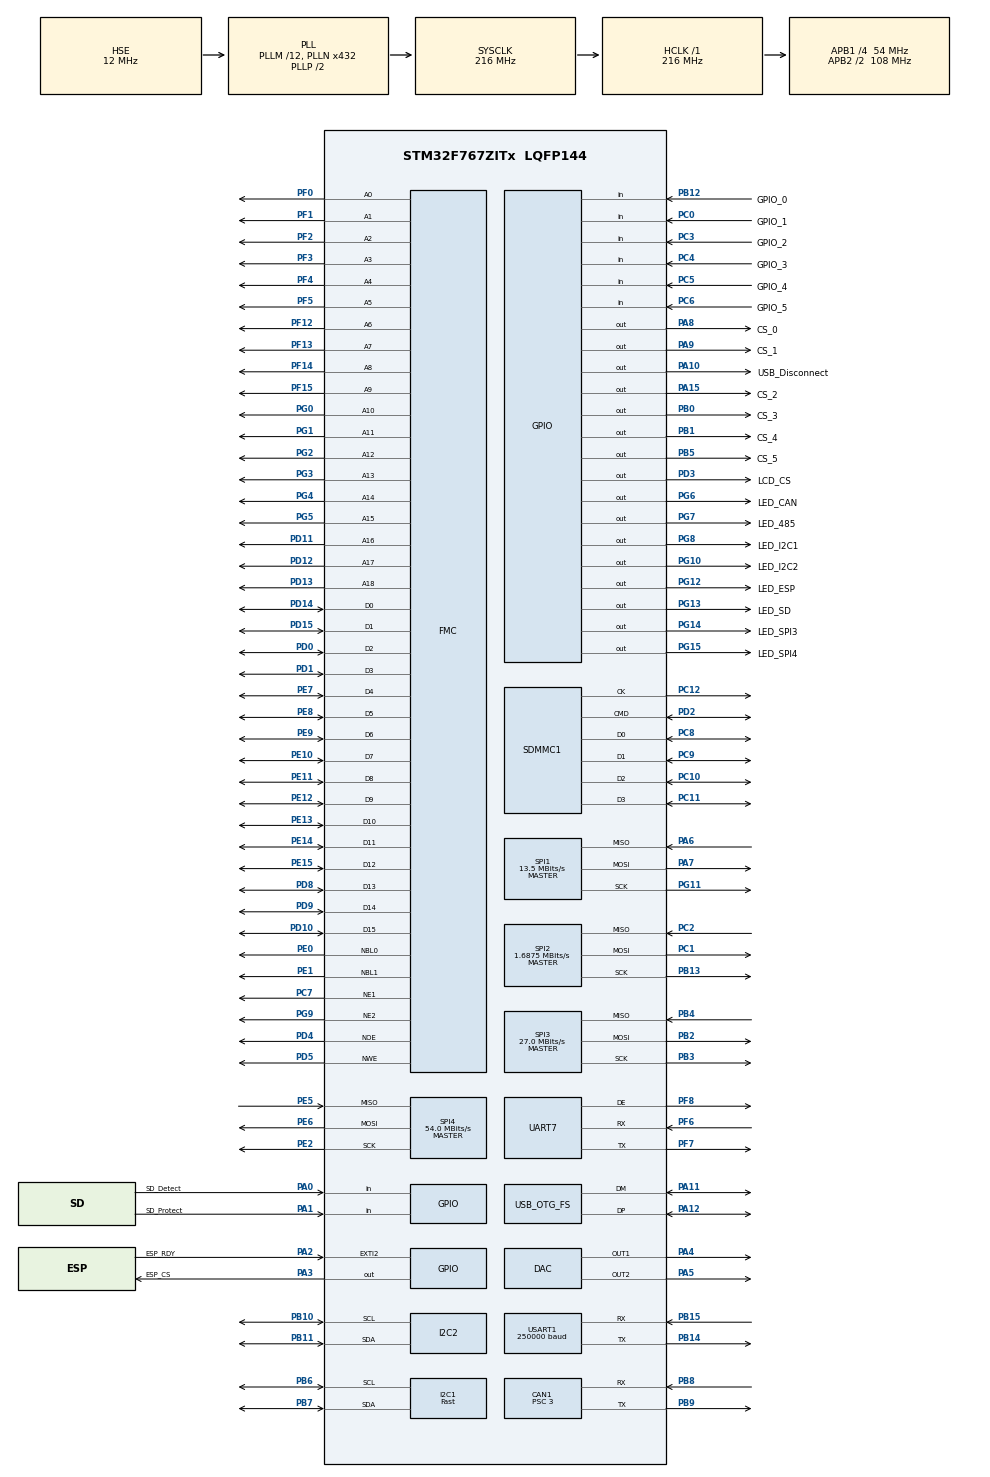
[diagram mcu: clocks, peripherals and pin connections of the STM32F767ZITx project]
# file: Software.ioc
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CAN1.BS1=CAN_BS1_15TQ
CAN1.BS2=CAN_BS2_2TQ
CAN1.CalculateBaudRate=1000000
CAN1.CalculateTimeBit=1000
CAN1.CalculateTimeQuantum=55.55555555555556
CAN1.NART=DISABLE
CAN1.Prescaler=3
Dma.Request0=USART1_TX
Dma.USART1_TX.0.Direction=DMA_MEMORY_TO_PERIPH
Dma.USART1_TX.0.FIFOMode=DMA_FIFOMODE_DISABLE
Dma.USART1_TX.0.Instance=DMA2_Stream7
Dma.USART1_TX.0.MemDataAlignment=DMA_MDATAALIGN_BYTE
Dma.USART1_TX.0.MemInc=DMA_MINC_ENABLE
Dma.USART1_TX.0.Mode=DMA_NORMAL
Dma.USART1_TX.0.PeriphDataAlignment=DMA_PDATAALIGN_BYTE
Dma.USART1_TX.0.PeriphInc=DMA_PINC_DISABLE
Dma.USART1_TX.0.Priority=DMA_PRIORITY_MEDIUM
FMC.ExtendedMode1=FMC_EXTENDED_MODE_DISABLE
I2C1.I2C_Speed_Mode=I2C_Fast
I2C1.Timing=0x6000030D
I2C2.Timing=0x20404768
Mcu.Family=STM32F7
Mcu.Name=STM32F767ZITx
Mcu.Package=LQFP144
NVIC.CAN1_RX0_IRQn=true\:0\:0\:false\:false\:true\:true\:true\:true
NVIC.DMA2_Stream7_IRQn=true\:0\:0\:false\:false\:true\:false\:true\:true
NVIC.OTG_FS_IRQn=true\:0\:0\:false\:false\:true\:true\:true\:true
NVIC.PriorityGroup=NVIC_PRIORITYGROUP_4
NVIC.USART1_IRQn=true\:0\:0\:false\:false\:true\:true\:true\:true
PA0/WKUP.GPIO_Label=SD_Detect
PA0/WKUP.Signal=GPIO_Input
PA1.GPIO_Label=SD_Protect
PA1.Signal=GPIO_Input
PA10.GPIO_Label=USB_Disconnect
PA10.Signal=GPIO_Output
PA11.Mode=Device_Only
PA11.Signal=USB_OTG_FS_DM
PA12.Mode=Device_Only
PA12.Signal=USB_OTG_FS_DP
PA13.Mode=Serial_Wire
PA13.Signal=SYS_JTMS-SWDIO
PA14.Mode=Serial_Wire
PA14.Signal=SYS_JTCK-SWCLK
PA15.GPIO_Label=CS_2
PA15.Signal=GPIO_Output
PA2.GPIO_Label=ESP_RDY
PA2.Signal=GPXTI2
PA3.GPIO_Label=ESP_CS
PA3.Signal=GPIO_Output
PA4.Signal=COMP_DAC1_group
PA5.Signal=COMP_DAC2_group
PA6.Mode=Full_Duplex_Master
PA6.Signal=SPI1_MISO
PA7.Mode=Full_Duplex_Master
PA7.Signal=SPI1_MOSI
PA8.GPIO_Label=CS_0
PA8.Signal=GPIO_Output
PA9.GPIO_Label=CS_1
PA9.Signal=GPIO_Output
PB0.GPIO_Label=CS_3
PB0.Signal=GPIO_Output
PB1.GPIO_Label=CS_4
PB1.Signal=GPIO_Output
PB10.Mode=I2C
PB10.Signal=I2C2_SCL
PB11.Mode=I2C
PB11.Signal=I2C2_SDA
PB12.GPIO_Label=GPIO_0
PB12.Signal=GPIO_Input
PB13.Mode=Full_Duplex_Master
PB13.Signal=SPI2_SCK
PB14.Mode=Asynchronous
PB14.Signal=USART1_TX
PB15.Mode=Asynchronous
PB15.Signal=USART1_RX
PB2.Mode=Full_Duplex_Master
PB2.Signal=SPI3_MOSI
PB3.Mode=Full_Duplex_Master
PB3.Signal=SPI3_SCK
PB4.Mode=Full_Duplex_Master
PB4.Signal=SPI3_MISO
PB5.GPIO_Label=CS_5
PB5.Signal=GPIO_Output
PB6.Mode=I2C
PB6.Signal=I2C1_SCL
PB7.Mode=I2C
PB7.Signal=I2C1_SDA
PB8.Mode=CAN_Activate
PB8.Signal=CAN1_RX
PB9.Mode=CAN_Activate
PB9.Signal=CAN1_TX
PC0.GPIO_Label=GPIO_1
PC0.Signal=GPIO_Input
PC1.Mode=Full_Duplex_Master
PC1.Signal=SPI2_MOSI
PC10.Mode=SD_4_bits_Wide_bus
PC10.Signal=SDMMC1_D2
PC11.Mode=SD_4_bits_Wide_bus
PC11.Signal=SDMMC1_D3
PC12.Mode=SD_4_bits_Wide_bus
PC12.Signal=SDMMC1_CK
PC2.Mode=Full_Duplex_Master
PC2.Signal=SPI2_MISO
PC3.GPIO_Label=GPIO_2
PC3.Signal=GPIO_Input
PC4.GPIO_Label=GPIO_3
PC4.Signal=GPIO_Input
PC5.GPIO_Label=GPIO_4
PC5.Signal=GPIO_Input
PC6.GPIO_Label=GPIO_5
PC6.Signal=GPIO_Input
PC7.Mode=NorPsramChipSelect1_1
PC7.Signal=FMC_NE1
PC8.Mode=SD_4_bits_Wide_bus
PC8.Signal=SDMMC1_D0
PC9.Mode=SD_4_bits_Wide_bus
PC9.Signal=SDMMC1_D1
PD0.Signal=FMC_D2_DA2
PD1.Signal=FMC_D3_DA3
PD10.Signal=FMC_D15_DA15
PD11.Signal=FMC_A16_CLE
PD12.Signal=FMC_A17_ALE
PD13.Signal=FMC_A18
PD14.Signal=FMC_D0_DA0
PD15.Signal=FMC_D1_DA1
PD2.Mode=SD_4_bits_Wide_bus
PD2.Signal=SDMMC1_CMD
PD3.GPIO_Label=LCD_CS
PD3.PinState=GPIO_PIN_SET
PD3.Signal=GPIO_Output
PD4.Signal=FMC_NOE
PD5.Signal=FMC_NWE
PD8.Signal=FMC_D13_DA13
PD9.Signal=FMC_D14_DA14
PE0.Signal=FMC_NBL0
PE1.Signal=FMC_NBL1
PE10.Signal=FMC_D7_DA7
PE11.Signal=FMC_D8_DA8
PE12.Signal=FMC_D9_DA9
PE13.Signal=FMC_D10_DA10
PE14.Signal=FMC_D11_DA11
PE15.Signal=FMC_D12_DA12
PE2.Mode=Full_Duplex_Master
PE2.Signal=SPI4_SCK
PE5.Mode=Full_Duplex_Master
PE5.Signal=SPI4_MISO
PE6.Mode=Full_Duplex_Master
PE6.Signal=SPI4_MOSI
PE7.Signal=FMC_D4_DA4
PE8.Signal=FMC_D5_DA5
PE9.Signal=FMC_D6_DA6
PF0.Signal=FMC_A0
PF1.Signal=FMC_A1
PF12.Signal=FMC_A6
PF13.Signal=FMC_A7
PF14.Signal=FMC_A8
PF15.Signal=FMC_A9
PF2.Signal=FMC_A2
PF3.Signal=FMC_A3
PF4.Signal=FMC_A4
PF5.Signal=FMC_A5
PF6.Mode=Asynchronous
PF6.Signal=UART7_RX
PF7.Mode=Asynchronous
PF7.Signal=UART7_TX
PF8.Mode=Hardware Flow Control (RS485)
PF8.Signal=UART7_DE
PG0.Signal=FMC_A10
PG1.Signal=FMC_A11
PG10.GPIO_Label=LED_I2C2
PG10.Signal=GPIO_Output
PG11.Mode=Full_Duplex_Master
PG11.Signal=SPI1_SCK
PG12.GPIO_Label=LED_ESP
PG12.Signal=GPIO_Output
PG13.GPIO_Label=LED_SD
PG13.Signal=GPIO_Output
PG14.GPIO_Label=LED_SPI3
PG14.Signal=GPIO_Output
PG15.GPIO_Label=LED_SPI4
PG15.Signal=GPIO_Output
PG2.Signal=FMC_A12
PG3.Signal=FMC_A13
PG4.Signal=FMC_A14_BA0
PG5.Signal=FMC_A15_BA1
PG6.GPIO_Label=LED_CAN
PG6.Signal=GPIO_Output
PG7.GPIO_Label=LED_485
PG7.Signal=GPIO_Output
PG8.GPIO_Label=LED_I2C1
PG8.Signal=GPIO_Output
PG9.Mode=NorPsramChipSelect2_2
PG9.Signal=FMC_NE2
PH0/OSC_IN.Mode=HSE-External-Oscillator
PH0/OSC_IN.Signal=RCC_OSC_IN
PH1/OSC_OUT.Mode=HSE-External-Oscillator
PH1/OSC_OUT.Signal=RCC_OSC_OUT
ProjectManager.HeapSize=0x200
ProjectManager.StackSize=0x400
ProjectManager.TargetToolchain=Other Toolchains (GPDSC)
RCC.AHBFreq_Value=216000000
RCC.APB1CLKDivider=RCC_HCLK_DIV4
RCC.APB1Freq_Value=54000000
RCC.APB1TimFreq_Value=108000000
RCC.APB2CLKDivider=RCC_HCLK_DIV2
RCC.APB2Freq_Value=108000000
RCC.APB2TimFreq_Value=216000000
RCC.CortexFreq_Value=216000000
RCC.HCLKFreq_Value=216000000
RCC.HSE_VALUE=12000000
RCC.HSI_VALUE=16000000
RCC.LSE_VALUE=32768
RCC.PLLM=12
RCC.PLLN=432
RCC.PLLQ=9
RCC.PLLSAIN=96
RCC.RCC_RTC_Clock_Source_FROM_HSE=RCC_RTCCLKSOURCE_HSE_DIV30
RCC.SDMMCClockSelection=RCC_SDMMC1CLKSOURCE_CLK48
RCC.SYSCLKFreq_VALUE=216000000
RCC.SYSCLKSource=RCC_SYSCLKSOURCE_PLLCLK
RCC.USBFreq_Value=48000000
RCC.VCOOutputFreq_Value=432000000
RTC.SynchPrediv=0xff
SH.COMP_DAC1_group.0=DAC_OUT1,DAC_OUT1
SH.COMP_DAC2_group.0=DAC_OUT2,DAC_OUT2
SH.FMC_A0.0=FMC_A0,19b-a2
SH.FMC_A0.1=FMC_A0,A0_1
SH.FMC_A1.0=FMC_A1,19b-a2
SH.FMC_A10.0=FMC_A10,19b-a2
SH.FMC_A11.0=FMC_A11,19b-a2
SH.FMC_A12.0=FMC_A12,19b-a2
SH.FMC_A13.0=FMC_A13,19b-a2
SH.FMC_A14_BA0.0=FMC_A14,19b-a2
SH.FMC_A15_BA1.0=FMC_A15,19b-a2
SH.FMC_A16_CLE.0=FMC_A16,19b-a2
SH.FMC_A17_ALE.0=FMC_A17,19b-a2
SH.FMC_A18.0=FMC_A18,19b-a2
SH.FMC_A2.0=FMC_A2,19b-a2
SH.FMC_A3.0=FMC_A3,19b-a2
SH.FMC_A4.0=FMC_A4,19b-a2
SH.FMC_A5.0=FMC_A5,19b-a2
SH.FMC_A6.0=FMC_A6,19b-a2
SH.FMC_A7.0=FMC_A7,19b-a2
SH.FMC_A8.0=FMC_A8,19b-a2
SH.FMC_A9.0=FMC_A9,19b-a2
SH.FMC_D0_DA0.0=FMC_D0,16b-d1
SH.FMC_D0_DA0.1=FMC_D0,16b-d2
SH.FMC_D10_DA10.0=FMC_D10,16b-d1
SH.FMC_D10_DA10.1=FMC_D10,16b-d2
SH.FMC_D11_DA11.0=FMC_D11,16b-d1
SH.FMC_D11_DA11.1=FMC_D11,16b-d2
SH.FMC_D12_DA12.0=FMC_D12,16b-d1
SH.FMC_D12_DA12.1=FMC_D12,16b-d2
SH.FMC_D13_DA13.0=FMC_D13,16b-d1
SH.FMC_D13_DA13.1=FMC_D13,16b-d2
SH.FMC_D14_DA14.0=FMC_D14,16b-d1
SH.FMC_D14_DA14.1=FMC_D14,16b-d2
SH.FMC_D15_DA15.0=FMC_D15,16b-d1
SH.FMC_D15_DA15.1=FMC_D15,16b-d2
SH.FMC_D1_DA1.0=FMC_D1,16b-d1
SH.FMC_D1_DA1.1=FMC_D1,16b-d2
SH.FMC_D2_DA2.0=FMC_D2,16b-d1
SH.FMC_D2_DA2.1=FMC_D2,16b-d2
SH.FMC_D3_DA3.0=FMC_D3,16b-d1
SH.FMC_D3_DA3.1=FMC_D3,16b-d2
SH.FMC_D4_DA4.0=FMC_D4,16b-d1
SH.FMC_D4_DA4.1=FMC_D4,16b-d2
SH.FMC_D5_DA5.0=FMC_D5,16b-d1
SH.FMC_D5_DA5.1=FMC_D5,16b-d2
SH.FMC_D6_DA6.0=FMC_D6,16b-d1
SH.FMC_D6_DA6.1=FMC_D6,16b-d2
SH.FMC_D7_DA7.0=FMC_D7,16b-d1
SH.FMC_D7_DA7.1=FMC_D7,16b-d2
SH.FMC_D8_DA8.0=FMC_D8,16b-d1
SH.FMC_D8_DA8.1=FMC_D8,16b-d2
SH.FMC_D9_DA9.0=FMC_D9,16b-d1
SH.FMC_D9_DA9.1=FMC_D9,16b-d2
SH.FMC_NBL0.0=FMC_NBL0,2ByteEnable2
SH.FMC_NBL1.0=FMC_NBL1,2ByteEnable2
SH.FMC_NOE.0=FMC_NOE,Lcd1
SH.FMC_NOE.1=FMC_NOE,Sram2
SH.FMC_NWE.0=FMC_NWE,Lcd1
SH.FMC_NWE.1=FMC_NWE,Sram2
SPI1.BaudRatePrescaler=SPI_BAUDRATEPRESCALER_8
SPI1.CalculateBaudRate=13.5 MBits/s
SPI1.DataSize=SPI_DATASIZE_8BIT
SPI1.Direction=SPI_DIRECTION_2LINES
SPI1.Mode=SPI_MODE_MASTER
SPI1.VirtualType=VM_MASTER
SPI2.BaudRatePrescaler=SPI_BAUDRATEPRESCALER_32
SPI2.CalculateBaudRate=1.6875 MBits/s
SPI2.Direction=SPI_DIRECTION_2LINES
SPI2.Mode=SPI_MODE_MASTER
SPI2.VirtualType=VM_MASTER
SPI3.BaudRatePrescaler=SPI_BAUDRATEPRESCALER_2
SPI3.CalculateBaudRate=27.0 MBits/s
SPI3.Direction=SPI_DIRECTION_2LINES
SPI3.Mode=SPI_MODE_MASTER
SPI3.VirtualType=VM_MASTER
SPI4.BaudRatePrescaler=SPI_BAUDRATEPRESCALER_2
SPI4.CalculateBaudRate=54.0 MBits/s
SPI4.Direction=SPI_DIRECTION_2LINES
SPI4.Mode=SPI_MODE_MASTER
SPI4.VirtualType=VM_MASTER
TIM1.Prescaler=216
USART1.BaudRate=250000
USART1.VirtualMode-Asynchronous=VM_ASYNC
USB_DEVICE.CLASS_NAME_FS=CDC
USB_DEVICE.VirtualMode-CDC_FS=Cdc
USB_DEVICE.VirtualModeFS=Cdc_FS
USB_OTG_FS.VirtualMode=Device_Only
VP_FATFS_VS_SDIO.Mode=SDIO
VP_RTC_VS_RTC_Activate.Mode=RTC_Enabled
VP_RTC_VS_RTC_Calendar.Mode=RTC_Calendar
VP_TIM1_VS_ClockSourceINT.Mode=Internal
VP_USB_DEVICE_VS_USB_DEVICE_CDC_FS.Mode=CDC_FS
board=custom

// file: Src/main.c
/* USER CODE BEGIN Header */
/**
  ******************************************************************************
  * @file           : main.c
  * @brief          : Main program body
  ******************************************************************************
  * @attention
  *
  * <h2><center>&copy; Copyright (c) 2022 STMicroelectronics.
  * All rights reserved.</center></h2>
  *
  * This software component is licensed by ST under Ultimate Liberty license
  * SLA0044, the "License"; You may not use this file except in compliance with
  * the License. You may obtain a copy of the License at:
  *                             www.st.com/SLA0044
  *
  ******************************************************************************
  */
/* USER CODE END Header */
#include "main.h"
#include "can.h"
#include "dac.h"
#include "dma.h"
#include "fatfs.h"
#include "i2c.h"
#include "rtc.h"
#include "sdmmc.h"
#include "spi.h"
#include "tim.h"
#include "usart.h"
#include "usb_device.h"
#include "gpio.h"
#include "fmc.h"

/* USER CODE BEGIN Includes */
#include "usbd_cdc_if.h"
#include "tft.h"
#include "modlab.h"
#include <stdio.h>
#include "usb_mon.h"

/* USER CODE END Includes */

/* USER CODE BEGIN PV */

uint16_t counter;
uint32_t tick_loop;
uint32_t tick_loop_old;

uint8_t address = 0;

/* USER CODE END PV */

void SystemClock_Config(void);

int main(void)
{

  /* MCU Configuration--------------------------------------------------------*/

  /* Reset of all peripherals, Initializes the Flash interface and the Systick. */
  HAL_Init();

  /* Configure the system clock */
  SystemClock_Config();

  /* Initialize all configured peripherals */
  MX_GPIO_Init();
  MX_SDMMC1_SD_Init();
  MX_FATFS_Init();
  MX_CAN1_Init();
  MX_I2C1_Init();
  MX_I2C2_Init();
  MX_RTC_Init();
  MX_SPI1_Init();
  MX_SPI2_Init();
  MX_UART7_Init();
  MX_DAC_Init();
  MX_FMC_Init();
  MX_SPI3_Init();
  MX_SPI4_Init();
  MX_TIM1_Init();
  MX_USB_DEVICE_Init();
  MX_DMA_Init();
  MX_USART1_UART_Init();
  /* USER CODE BEGIN 2 */

  timer_init();

  LEDs_Off();
  HAL_GPIO_WritePin(USB_Disconnect_GPIO_Port, USB_Disconnect_Pin, 1);
  HAL_Delay(200);
  //HAL_GPIO_WritePin(USB_Disconnect_GPIO_Port, USB_Disconnect_Pin, 0);

  CAN_Filter();
  HAL_CAN_Start(&hcan1);
  HAL_CAN_ActivateNotification(&hcan1, CAN_IT_RX_FIFO0_MSG_PENDING);

  tft_init();
  HAL_UART_Receive_IT(&huart1, RxBuffer, 1); // Get TFT Command
  __enable_irq();

  HAL_Delay(500);
	scan_dev();

//https://controllerstech.com/can-protocol-in-stm32/

  HAL_Delay(500);
  tft_reset();

  tick_loop = HAL_GetTick() + 1000;
  /* USER CODE END 2 */

  /* Infinite loop */
  /* USER CODE BEGIN WHILE */
  while (1)
  {
    if((tft_cmd == CMD_PAGESET) && (setdata == 1))
    {
      HAL_Delay(10);
      enableblock = 1;
      setdata = 0;
    }

    switch (tft_page)
    {
      case PAGE_MAIN:
        main_page_loop();
        break;
      case PAGE_DTEST:
        diode_page_loop();
        break;
      case PAGE_FGEN:
        fgen_page_loop();
        break;
      case PAGE_SYMPSU:
        sympsu_page_loop();
        break;
      case PAGE_SMPS:
        smps_page_loop();
        break;
      case PAGE_LOAD:
        load_page_loop();
        break;
    }

    if(tick_loop < (HAL_GetTick() - 1000))
    {
      tick_loop = HAL_GetTick();
      sprintf(out_buf, "USB Test Zyklus, Tick-Time = %d\n", HAL_GetTick());
      CDC_Transmit_FS((uint8_t *)out_buf, strlen(out_buf));
    }

  }
  /* USER CODE END 3 */
}

void SystemClock_Config(void)
{
  RCC_OscInitTypeDef RCC_OscInitStruct = {0};
  RCC_ClkInitTypeDef RCC_ClkInitStruct = {0};
  RCC_PeriphCLKInitTypeDef PeriphClkInitStruct = {0};

  /** Configure the main internal regulator output voltage
  */
  __HAL_RCC_PWR_CLK_ENABLE();
  __HAL_PWR_VOLTAGESCALING_CONFIG(PWR_REGULATOR_VOLTAGE_SCALE1);
  /** Initializes the RCC Oscillators according to the specified parameters
  * in the RCC_OscInitTypeDef structure.
  */
  RCC_OscInitStruct.OscillatorType = RCC_OSCILLATORTYPE_LSI|RCC_OSCILLATORTYPE_HSE;
  RCC_OscInitStruct.HSEState = RCC_HSE_ON;
  RCC_OscInitStruct.LSIState = RCC_LSI_ON;
  RCC_OscInitStruct.PLL.PLLState = RCC_PLL_ON;
  RCC_OscInitStruct.PLL.PLLSource = RCC_PLLSOURCE_HSE;
  RCC_OscInitStruct.PLL.PLLM = 12;
  RCC_OscInitStruct.PLL.PLLN = 432;
  RCC_OscInitStruct.PLL.PLLP = RCC_PLLP_DIV2;
  RCC_OscInitStruct.PLL.PLLQ = 9;
  RCC_OscInitStruct.PLL.PLLR = 2;
  if (HAL_RCC_OscConfig(&RCC_OscInitStruct) != HAL_OK)
  {
    Error_Handler();
  }
  /** Activate the Over-Drive mode
  */
  if (HAL_PWREx_EnableOverDrive() != HAL_OK)
  {
    Error_Handler();
  }
  /** Initializes the CPU, AHB and APB buses clocks
  */
  RCC_ClkInitStruct.ClockType = RCC_CLOCKTYPE_HCLK|RCC_CLOCKTYPE_SYSCLK
                              |RCC_CLOCKTYPE_PCLK1|RCC_CLOCKTYPE_PCLK2;
  RCC_ClkInitStruct.SYSCLKSource = RCC_SYSCLKSOURCE_PLLCLK;
  RCC_ClkInitStruct.AHBCLKDivider = RCC_SYSCLK_DIV1;
  RCC_ClkInitStruct.APB1CLKDivider = RCC_HCLK_DIV4;
  RCC_ClkInitStruct.APB2CLKDivider = RCC_HCLK_DIV2;

  if (HAL_RCC_ClockConfig(&RCC_ClkInitStruct, FLASH_LATENCY_7) != HAL_OK)
  {
    Error_Handler();
  }
  PeriphClkInitStruct.PeriphClockSelection = RCC_PERIPHCLK_RTC|RCC_PERIPHCLK_USART1
                              |RCC_PERIPHCLK_UART7|RCC_PERIPHCLK_I2C1
                              |RCC_PERIPHCLK_I2C2|RCC_PERIPHCLK_SDMMC1
                              |RCC_PERIPHCLK_CLK48;
  PeriphClkInitStruct.RTCClockSelection = RCC_RTCCLKSOURCE_LSI;
  PeriphClkInitStruct.Usart1ClockSelection = RCC_USART1CLKSOURCE_PCLK2;
  PeriphClkInitStruct.Uart7ClockSelection = RCC_UART7CLKSOURCE_PCLK1;
  PeriphClkInitStruct.I2c1ClockSelection = RCC_I2C1CLKSOURCE_PCLK1;
  PeriphClkInitStruct.I2c2ClockSelection = RCC_I2C2CLKSOURCE_PCLK1;
  PeriphClkInitStruct.Clk48ClockSelection = RCC_CLK48SOURCE_PLL;
  PeriphClkInitStruct.Sdmmc1ClockSelection = RCC_SDMMC1CLKSOURCE_CLK48;
  if (HAL_RCCEx_PeriphCLKConfig(&PeriphClkInitStruct) != HAL_OK)
  {
    Error_Handler();
  }
}

/* USER CODE BEGIN 4 */

void HAL_UART_RxCpltCallback(UART_HandleTypeDef *huart)
{

  /**
   * TFT Interrupt Functions
  */
  tft_parse();

}

void HAL_CAN_RxFifo0MsgPendingCallback(CAN_HandleTypeDef *hcan)
{
  if (HAL_CAN_GetRxMessage(hcan, CAN_RX_FIFO0, &RxHeader, RxData) != HAL_OK)
  {
    Error_Handler();
  }

  can_parse();
}

void CAN_Filter (void)
{
  //no filtering, Message types decoded in interrupt
  CAN_FilterTypeDef canfilterconfig;

  canfilterconfig.FilterActivation = CAN_FILTER_ENABLE;
  canfilterconfig.FilterBank = 0;
  canfilterconfig.FilterFIFOAssignment = CAN_FILTER_FIFO0;
  canfilterconfig.FilterIdHigh = 0x0000;
  canfilterconfig.FilterIdLow = 0;
  canfilterconfig.FilterMaskIdHigh = 0;
  canfilterconfig.FilterMaskIdLow = 0x0000;
  canfilterconfig.FilterMode = CAN_FILTERMODE_IDMASK;
  canfilterconfig.FilterScale = CAN_FILTERSCALE_32BIT;
  canfilterconfig.SlaveStartFilterBank = 1;

  HAL_CAN_ConfigFilter(&hcan1, &canfilterconfig);
}

void LEDs_Off(void)
{
  HAL_GPIO_WritePin(LED_CAN_GPIO_Port,  LED_CAN_Pin,  0);   //CAN
  HAL_GPIO_WritePin(LED_485_GPIO_Port,  LED_485_Pin,  0);   //485
  HAL_GPIO_WritePin(LED_I2C1_GPIO_Port, LED_I2C1_Pin, 0);   //I2C1
  HAL_GPIO_WritePin(LED_I2C2_GPIO_Port, LED_I2C2_Pin, 0);   //I2C1
  HAL_GPIO_WritePin(LED_ESP_GPIO_Port,  LED_ESP_Pin,  0);   //ESP
  HAL_GPIO_WritePin(LED_SD_GPIO_Port,   LED_SD_Pin,   0);   //SD
  HAL_GPIO_WritePin(LED_SPI3_GPIO_Port, LED_SPI3_Pin, 0);   //SPI3
  HAL_GPIO_WritePin(LED_SPI4_GPIO_Port, LED_SPI4_Pin, 0);   //SPI4
}

/* USER CODE END 4 */

void Error_Handler(void)
{
  __disable_irq();
  while (1)
  {
  }
}

/************************ (C) COPYRIGHT STMicroelectronics *****END OF FILE****/
